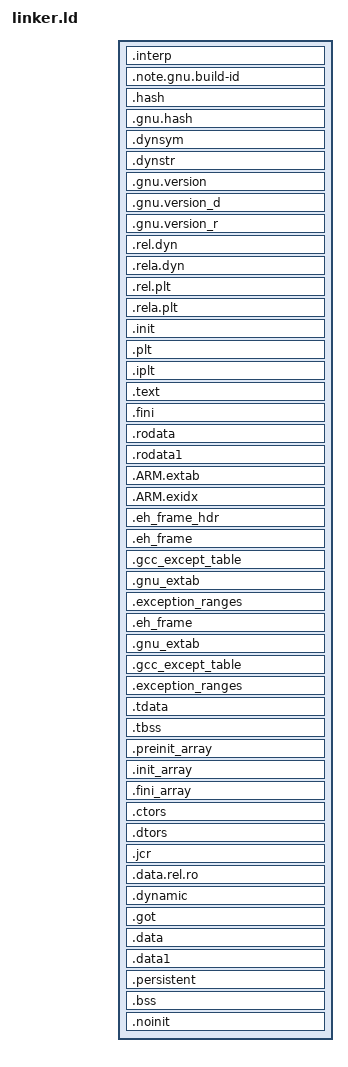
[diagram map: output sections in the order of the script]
/* Copyright (C) 2014-2022 Free Software Foundation, Inc.
   Copying and distribution of this script, with or without modification,
   are permitted in any medium without royalty provided the copyright
   notice and this notice are preserved.  */
OUTPUT_FORMAT("elf32-littlearm", "elf32-bigarm",
              "elf32-littlearm")
OUTPUT_ARCH(arm)
ENTRY(_my_start)
SEARCH_DIR("/usr/lib/arm-none-eabi/lib");
SECTIONS
{
  /* Read-only sections, merged into text segment: */
  PROVIDE (__executable_start = SEGMENT_START("text-segment", 0x100000)); . = SEGMENT_START("text-segment", 0x100000);
  .interp         : { *(.interp) }
  .note.gnu.build-id  : { *(.note.gnu.build-id) }
  .hash           : { *(.hash) }
  .gnu.hash       : { *(.gnu.hash) }
  .dynsym         : { *(.dynsym) }
  .dynstr         : { *(.dynstr) }
  .gnu.version    : { *(.gnu.version) }
  .gnu.version_d  : { *(.gnu.version_d) }
  .gnu.version_r  : { *(.gnu.version_r) }
  .rel.dyn        :
    {
      *(.rel.init)
      *(.rel.text .rel.text.* .rel.gnu.linkonce.t.*)
      *(.rel.fini)
      *(.rel.rodata .rel.rodata.* .rel.gnu.linkonce.r.*)
      *(.rel.data.rel.ro .rel.data.rel.ro.* .rel.gnu.linkonce.d.rel.ro.*)
      *(.rel.data .rel.data.* .rel.gnu.linkonce.d.*)
      *(.rel.tdata .rel.tdata.* .rel.gnu.linkonce.td.*)
      *(.rel.tbss .rel.tbss.* .rel.gnu.linkonce.tb.*)
      *(.rel.ctors)
      *(.rel.dtors)
      *(.rel.got)
      *(.rel.bss .rel.bss.* .rel.gnu.linkonce.b.*)
      PROVIDE_HIDDEN (__rel_iplt_start = .);
      *(.rel.iplt)
      PROVIDE_HIDDEN (__rel_iplt_end = .);
    }
  .rela.dyn       :
    {
      *(.rela.init)
      *(.rela.text .rela.text.* .rela.gnu.linkonce.t.*)
      *(.rela.fini)
      *(.rela.rodata .rela.rodata.* .rela.gnu.linkonce.r.*)
      *(.rela.data .rela.data.* .rela.gnu.linkonce.d.*)
      *(.rela.tdata .rela.tdata.* .rela.gnu.linkonce.td.*)
      *(.rela.tbss .rela.tbss.* .rela.gnu.linkonce.tb.*)
      *(.rela.ctors)
      *(.rela.dtors)
      *(.rela.got)
      *(.rela.bss .rela.bss.* .rela.gnu.linkonce.b.*)
      PROVIDE_HIDDEN (__rela_iplt_start = .);
      *(.rela.iplt)
      PROVIDE_HIDDEN (__rela_iplt_end = .);
    }
  .rel.plt        :
    {
      *(.rel.plt)
    }
  .rela.plt       :
    {
      *(.rela.plt)
    }
  .init           :
  {
    KEEP (*(SORT_NONE(.init)))
  }
  .plt            : { *(.plt) }
  .iplt           : { *(.iplt) }
  .text           :
  {
    *(.text.unlikely .text.*_unlikely .text.unlikely.*)
    *(.text.exit .text.exit.*)
    *(.text.startup .text.startup.*)
    *(.text.hot .text.hot.*)
    *(SORT(.text.sorted.*))
    *(.text .stub .text.* .gnu.linkonce.t.*)
    /* .gnu.warning sections are handled specially by elf.em.  */
    *(.gnu.warning)
    *(.glue_7t) *(.glue_7) *(.vfp11_veneer) *(.v4_bx)
  }
  .fini           :
  {
    KEEP (*(SORT_NONE(.fini)))
  }
  PROVIDE (__etext = .);
  PROVIDE (_etext = .);
  PROVIDE (etext = .);
  .rodata         : { *(.rodata .rodata.* .gnu.linkonce.r.*) }
  .rodata1        : { *(.rodata1) }
  .ARM.extab   : { *(.ARM.extab* .gnu.linkonce.armextab.*) }
  .ARM.exidx   :
    {
      PROVIDE_HIDDEN (__exidx_start = .);
      *(.ARM.exidx* .gnu.linkonce.armexidx.*)
      PROVIDE_HIDDEN (__exidx_end = .);
    }
  .eh_frame_hdr   : { *(.eh_frame_hdr) *(.eh_frame_entry .eh_frame_entry.*) }
  .eh_frame       : ONLY_IF_RO { KEEP (*(.eh_frame)) *(.eh_frame.*) }
  .gcc_except_table   : ONLY_IF_RO { *(.gcc_except_table .gcc_except_table.*) }
  .gnu_extab   : ONLY_IF_RO { *(.gnu_extab*) }
  /* These sections are generated by the Sun/Oracle C++ compiler.  */
  .exception_ranges   : ONLY_IF_RO { *(.exception_ranges*) }
  /* Adjust the address for the data segment.  We want to adjust up to
     the same address within the page on the next page up.  */
  . = ALIGN(CONSTANT (MAXPAGESIZE)) + (. & (CONSTANT (MAXPAGESIZE) - 1));
  /* Exception handling  */
  .eh_frame       : ONLY_IF_RW { KEEP (*(.eh_frame)) *(.eh_frame.*) }
  .gnu_extab      : ONLY_IF_RW { *(.gnu_extab) }
  .gcc_except_table   : ONLY_IF_RW { *(.gcc_except_table .gcc_except_table.*) }
  .exception_ranges   : ONLY_IF_RW { *(.exception_ranges*) }
  /* Thread Local Storage sections  */
  .tdata          :
   {
     PROVIDE_HIDDEN (__tdata_start = .);
     *(.tdata .tdata.* .gnu.linkonce.td.*)
   }
  .tbss           : { *(.tbss .tbss.* .gnu.linkonce.tb.*) *(.tcommon) }
  .preinit_array    :
  {
    PROVIDE_HIDDEN (__preinit_array_start = .);
    KEEP (*(.preinit_array))
    PROVIDE_HIDDEN (__preinit_array_end = .);
  }
  .init_array    :
  {
    PROVIDE_HIDDEN (__init_array_start = .);
    KEEP (*(SORT_BY_INIT_PRIORITY(.init_array.*) SORT_BY_INIT_PRIORITY(.ctors.*)))
    KEEP (*(.init_array EXCLUDE_FILE (*crtbegin.o *crtbegin?.o *crtend.o *crtend?.o ) .ctors))
    PROVIDE_HIDDEN (__init_array_end = .);
  }
  .fini_array    :
  {
    PROVIDE_HIDDEN (__fini_array_start = .);
    KEEP (*(SORT_BY_INIT_PRIORITY(.fini_array.*) SORT_BY_INIT_PRIORITY(.dtors.*)))
    KEEP (*(.fini_array EXCLUDE_FILE (*crtbegin.o *crtbegin?.o *crtend.o *crtend?.o ) .dtors))
    PROVIDE_HIDDEN (__fini_array_end = .);
  }
  .ctors          :
  {
    /* gcc uses crtbegin.o to find the start of
       the constructors, so we make sure it is
       first.  Because this is a wildcard, it
       doesn't matter if the user does not
       actually link against crtbegin.o; the
       linker won't look for a file to match a
       wildcard.  The wildcard also means that it
       doesn't matter which directory crtbegin.o
       is in.  */
    KEEP (*crtbegin.o(.ctors))
    KEEP (*crtbegin?.o(.ctors))
    /* We don't want to include the .ctor section from
       the crtend.o file until after the sorted ctors.
       The .ctor section from the crtend file contains the
       end of ctors marker and it must be last */
    KEEP (*(EXCLUDE_FILE (*crtend.o *crtend?.o ) .ctors))
    KEEP (*(SORT(.ctors.*)))
    KEEP (*(.ctors))
  }
  .dtors          :
  {
    KEEP (*crtbegin.o(.dtors))
    KEEP (*crtbegin?.o(.dtors))
    KEEP (*(EXCLUDE_FILE (*crtend.o *crtend?.o ) .dtors))
    KEEP (*(SORT(.dtors.*)))
    KEEP (*(.dtors))
  }
  .jcr            : { KEEP (*(.jcr)) }
  .data.rel.ro : { *(.data.rel.ro.local* .gnu.linkonce.d.rel.ro.local.*) *(.data.rel.ro .data.rel.ro.* .gnu.linkonce.d.rel.ro.*) }
  .dynamic        : { *(.dynamic) }
  .got            : { *(.got.plt) *(.igot.plt) *(.got) *(.igot) }
  .data           :
  {
    __data_start = .;
    *(.data .data.* .gnu.linkonce.d.*)
    SORT(CONSTRUCTORS)
  }
  .data1          : { *(.data1) }
  _edata = .; PROVIDE (edata = .);
  /* This section contains data that is initialized during load,
     but not during the application's initialization sequence.  */
  .persistent :
  {
    . = ALIGN(32 / 8);
    PROVIDE (__persistent_start = .);
    *(.persistent .persistent.* .gnu.linkonce.p.*)
    . = ALIGN(32 / 8);
    PROVIDE (__persistent_end = .);
  }
  . = .;
  __bss_start = .;
  __bss_start__ = .;
  .bss            :
  {
   *(.dynbss)
   *(.bss .bss.* .gnu.linkonce.b.*)
   *(COMMON)
   /* Align here to ensure that the .bss section occupies space up to
      _end.  Align after .bss to ensure correct alignment even if the
      .bss section disappears because there are no input sections.
      FIXME: Why do we need it? When there is no .bss section, we do not
      pad the .data section.  */
   . = ALIGN(. != 0 ? 32 / 8 : 1);
  }
  _bss_end__ = .; __bss_end__ = .;
  /* This section contains data that is not initialized during load,
     or during the application's initialization sequence.  */
  .noinit (NOLOAD) :
  {
    . = ALIGN(32 / 8);
    PROVIDE (__noinit_start = .);
    *(.noinit .noinit.* .gnu.linkonce.n.*)
    . = ALIGN(32 / 8);
    PROVIDE (__noinit_end = .);
  }
  . = ALIGN(32 / 8);
  . = SEGMENT_START("ldata-segment", .);
  . = ALIGN(32 / 8);
  __end__ = .;
  _end = .; PROVIDE (end = .);
}

